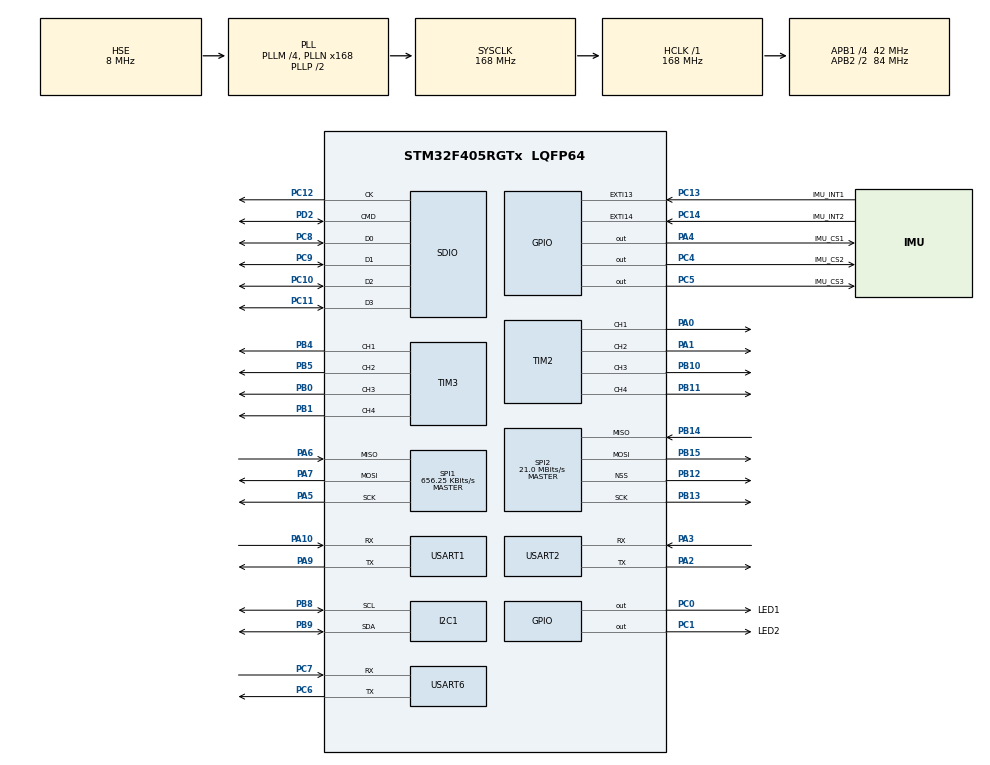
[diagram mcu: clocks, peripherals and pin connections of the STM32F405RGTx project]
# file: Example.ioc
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Mcu.Family=STM32F4
Mcu.Name=STM32F405RGTx
Mcu.Package=LQFP64
NVIC.PriorityGroup=NVIC_PRIORITYGROUP_4
PA0-WKUP.Signal=S_TIM2_CH1_ETR
PA1.Signal=S_TIM2_CH2
PA10.Mode=Asynchronous
PA10.Signal=USART1_RX
PA13.Mode=Serial_Wire
PA13.Signal=SYS_JTMS-SWDIO
PA14.Mode=Serial_Wire
PA14.Signal=SYS_JTCK-SWCLK
PA2.Mode=Asynchronous
PA2.Signal=USART2_TX
PA3.Mode=Asynchronous
PA3.Signal=USART2_RX
PA4.GPIO_Label=IMU_CS1
PA4.Signal=GPIO_Output
PA5.Mode=Full_Duplex_Master
PA5.Signal=SPI1_SCK
PA6.Mode=Full_Duplex_Master
PA6.Signal=SPI1_MISO
PA7.Mode=Full_Duplex_Master
PA7.Signal=SPI1_MOSI
PA9.Mode=Asynchronous
PA9.Signal=USART1_TX
PB0.Signal=S_TIM3_CH3
PB1.Signal=S_TIM3_CH4
PB10.Signal=S_TIM2_CH3
PB11.Signal=S_TIM2_CH4
PB12.Mode=NSS_Signal_Hard_Output
PB12.Signal=SPI2_NSS
PB13.Mode=Full_Duplex_Master
PB13.Signal=SPI2_SCK
PB14.Mode=Full_Duplex_Master
PB14.Signal=SPI2_MISO
PB15.Mode=Full_Duplex_Master
PB15.Signal=SPI2_MOSI
PB4.Signal=S_TIM3_CH1
PB5.Signal=S_TIM3_CH2
PB8.Mode=I2C
PB8.Signal=I2C1_SCL
PB9.Mode=I2C
PB9.Signal=I2C1_SDA
PC0.GPIO_Label=LED1
PC0.Signal=GPIO_Output
PC1.GPIO_Label=LED2
PC1.Signal=GPIO_Output
PC10.Mode=SD_4_bits_Wide_bus
PC10.Signal=SDIO_D2
PC11.Mode=SD_4_bits_Wide_bus
PC11.Signal=SDIO_D3
PC12.Mode=SD_4_bits_Wide_bus
PC12.Signal=SDIO_CK
PC13-ANTI_TAMP.GPIO_Label=IMU_INT1
PC13-ANTI_TAMP.Signal=GPXTI13
PC14-OSC32_IN.GPIO_Label=IMU_INT2
PC14-OSC32_IN.Signal=GPXTI14
PC4.GPIO_Label=IMU_CS2
PC4.Signal=GPIO_Output
PC5.GPIO_Label=IMU_CS3
PC5.Signal=GPIO_Output
PC6.Mode=Asynchronous
PC6.Signal=USART6_TX
PC7.Mode=Asynchronous
PC7.Signal=USART6_RX
PC8.Mode=SD_4_bits_Wide_bus
PC8.Signal=SDIO_D0
PC9.Mode=SD_4_bits_Wide_bus
PC9.Signal=SDIO_D1
PD2.Mode=SD_4_bits_Wide_bus
PD2.Signal=SDIO_CMD
PH0-OSC_IN.Mode=HSE-External-Oscillator
PH0-OSC_IN.Signal=RCC_OSC_IN
PH1-OSC_OUT.Mode=HSE-External-Oscillator
PH1-OSC_OUT.Signal=RCC_OSC_OUT
ProjectManager.HeapSize=0x200
ProjectManager.StackSize=0x400
ProjectManager.TargetToolchain=MDK-ARM V5
RCC.48MHZClocksFreq_Value=48000000
RCC.AHBFreq_Value=168000000
RCC.APB1CLKDivider=RCC_HCLK_DIV4
RCC.APB1Freq_Value=42000000
RCC.APB1TimFreq_Value=84000000
RCC.APB2CLKDivider=RCC_HCLK_DIV2
RCC.APB2Freq_Value=84000000
RCC.APB2TimFreq_Value=168000000
RCC.CortexFreq_Value=168000000
RCC.HCLKFreq_Value=168000000
RCC.HSE_VALUE=8000000
RCC.HSI_VALUE=16000000
RCC.LSE_VALUE=32768
RCC.PLLM=4
RCC.PLLN=168
RCC.PLLQ=7
RCC.PLLSourceVirtual=RCC_PLLSOURCE_HSE
RCC.SYSCLKFreq_VALUE=168000000
RCC.SYSCLKSource=RCC_SYSCLKSOURCE_PLLCLK
RCC.VCOOutputFreq_Value=336000000
SH.S_TIM2_CH1_ETR.0=TIM2_CH1,Output Compare1 CH1
SH.S_TIM2_CH2.0=TIM2_CH2,Output Compare2 CH2
SH.S_TIM2_CH3.0=TIM2_CH3,Output Compare3 CH3
SH.S_TIM2_CH4.0=TIM2_CH4,Output Compare4 CH4
SH.S_TIM3_CH1.0=TIM3_CH1,Output Compare1 CH1
SH.S_TIM3_CH2.0=TIM3_CH2,Output Compare2 CH2
SH.S_TIM3_CH3.0=TIM3_CH3,Output Compare3 CH3
SH.S_TIM3_CH4.0=TIM3_CH4,Output Compare4 CH4
SPI1.BaudRatePrescaler=SPI_BAUDRATEPRESCALER_128
SPI1.CalculateBaudRate=656.25 KBits/s
SPI1.Direction=SPI_DIRECTION_2LINES
SPI1.Mode=SPI_MODE_MASTER
SPI1.VirtualType=VM_MASTER
SPI2.CalculateBaudRate=21.0 MBits/s
SPI2.Direction=SPI_DIRECTION_2LINES
SPI2.Mode=SPI_MODE_MASTER
SPI2.VirtualNSS=VM_NSSHARD
SPI2.VirtualType=VM_MASTER
TIM2.Channel-Output\ Compare1\ CH1=TIM_CHANNEL_1
TIM2.Channel-Output\ Compare2\ CH2=TIM_CHANNEL_2
TIM2.Channel-Output\ Compare3\ CH3=TIM_CHANNEL_3
TIM2.Channel-Output\ Compare4\ CH4=TIM_CHANNEL_4
TIM3.Channel-Output\ Compare1\ CH1=TIM_CHANNEL_1
TIM3.Channel-Output\ Compare2\ CH2=TIM_CHANNEL_2
TIM3.Channel-Output\ Compare3\ CH3=TIM_CHANNEL_3
TIM3.Channel-Output\ Compare4\ CH4=TIM_CHANNEL_4
USART1.VirtualMode=VM_ASYNC
USART2.VirtualMode=VM_ASYNC
USART6.VirtualMode=VM_ASYNC
board=custom

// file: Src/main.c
/* USER CODE BEGIN Header */
/**
  ******************************************************************************
  * @file           : main.c
  * @brief          : Main program body
  ******************************************************************************
  ** This notice applies to any and all portions of this file
  * that are not between comment pairs USER CODE BEGIN and
  * USER CODE END. Other portions of this file, whether
  * inserted by the user or by software development tools
  * are owned by their respective copyright owners.
  *
  * COPYRIGHT(c) 2019 STMicroelectronics
  *
  * Redistribution and use in source and binary forms, with or without modification,
  * are permitted provided that the following conditions are met:
  *   1. Redistributions of source code must retain the above copyright notice,
  *      this list of conditions and the following disclaimer.
  *   2. Redistributions in binary form must reproduce the above copyright notice,
  *      this list of conditions and the following disclaimer in the documentation
  *      and/or other materials provided with the distribution.
  *   3. Neither the name of STMicroelectronics nor the names of its contributors
  *      may be used to endorse or promote products derived from this software
  *      without specific prior written permission.
  *
  * THIS SOFTWARE IS PROVIDED BY THE COPYRIGHT HOLDERS AND CONTRIBUTORS "AS IS"
  * AND ANY EXPRESS OR IMPLIED WARRANTIES, INCLUDING, BUT NOT LIMITED TO, THE
  * IMPLIED WARRANTIES OF MERCHANTABILITY AND FITNESS FOR A PARTICULAR PURPOSE ARE
  * DISCLAIMED. IN NO EVENT SHALL THE COPYRIGHT HOLDER OR CONTRIBUTORS BE LIABLE
  * FOR ANY DIRECT, INDIRECT, INCIDENTAL, SPECIAL, EXEMPLARY, OR CONSEQUENTIAL
  * DAMAGES (INCLUDING, BUT NOT LIMITED TO, PROCUREMENT OF SUBSTITUTE GOODS OR
  * SERVICES; LOSS OF USE, DATA, OR PROFITS; OR BUSINESS INTERRUPTION) HOWEVER
  * CAUSED AND ON ANY THEORY OF LIABILITY, WHETHER IN CONTRACT, STRICT LIABILITY,
  * OR TORT (INCLUDING NEGLIGENCE OR OTHERWISE) ARISING IN ANY WAY OUT OF THE USE
  * OF THIS SOFTWARE, EVEN IF ADVISED OF THE POSSIBILITY OF SUCH DAMAGE.
  *
  ******************************************************************************
  */
/* USER CODE END Header */

#include "main.h"

/* USER CODE BEGIN Includes */
#include "stdio.h"
/* USER CODE END Includes */

I2C_HandleTypeDef hi2c1;

SD_HandleTypeDef hsd;

SPI_HandleTypeDef hspi1;
SPI_HandleTypeDef hspi2;

TIM_HandleTypeDef htim2;
TIM_HandleTypeDef htim3;

UART_HandleTypeDef huart1;
UART_HandleTypeDef huart2;
UART_HandleTypeDef huart6;

/* USER CODE BEGIN PV */

//printf重定向
int fputc(int ch, FILE *f)
{
	HAL_UART_Transmit(&huart1, (uint8_t*) &ch,1, 10);
	return ch;
}
/* USER CODE END PV */

void SystemClock_Config(void);
static void MX_GPIO_Init(void);
static void MX_USART1_UART_Init(void);
static void MX_USART2_UART_Init(void);
static void MX_SPI1_Init(void);
static void MX_SDIO_SD_Init(void);
static void MX_USART6_UART_Init(void);
static void MX_SPI2_Init(void);
static void MX_I2C1_Init(void);
static void MX_TIM2_Init(void);
static void MX_TIM3_Init(void);

int main(void)
{

  /* MCU Configuration--------------------------------------------------------*/

  /* Reset of all peripherals, Initializes the Flash interface and the Systick. */
  HAL_Init();

  /* Configure the system clock */
  SystemClock_Config();

  /* Initialize all configured peripherals */
  MX_GPIO_Init();
  MX_USART1_UART_Init();
  MX_USART2_UART_Init();
  MX_SPI1_Init();
  MX_SDIO_SD_Init();
  MX_USART6_UART_Init();
  MX_SPI2_Init();
  MX_I2C1_Init();
  MX_TIM2_Init();
  MX_TIM3_Init();

  /* Infinite loop */
  /* USER CODE BEGIN WHILE */
  while (1)
  {
		printf("hello\n");
		HAL_Delay(500);
    /* USER CODE END WHILE */
  }
}

void SystemClock_Config(void)
{
  RCC_OscInitTypeDef RCC_OscInitStruct = {0};
  RCC_ClkInitTypeDef RCC_ClkInitStruct = {0};

  /**Configure the main internal regulator output voltage
  */
  __HAL_RCC_PWR_CLK_ENABLE();
  __HAL_PWR_VOLTAGESCALING_CONFIG(PWR_REGULATOR_VOLTAGE_SCALE1);
  /**Initializes the CPU, AHB and APB busses clocks
  */
  RCC_OscInitStruct.OscillatorType = RCC_OSCILLATORTYPE_HSE;
  RCC_OscInitStruct.HSEState = RCC_HSE_ON;
  RCC_OscInitStruct.PLL.PLLState = RCC_PLL_ON;
  RCC_OscInitStruct.PLL.PLLSource = RCC_PLLSOURCE_HSE;
  RCC_OscInitStruct.PLL.PLLM = 4;
  RCC_OscInitStruct.PLL.PLLN = 168;
  RCC_OscInitStruct.PLL.PLLP = RCC_PLLP_DIV2;
  RCC_OscInitStruct.PLL.PLLQ = 7;
  if (HAL_RCC_OscConfig(&RCC_OscInitStruct) != HAL_OK)
  {
    Error_Handler();
  }
  /**Initializes the CPU, AHB and APB busses clocks
  */
  RCC_ClkInitStruct.ClockType = RCC_CLOCKTYPE_HCLK|RCC_CLOCKTYPE_SYSCLK
                              |RCC_CLOCKTYPE_PCLK1|RCC_CLOCKTYPE_PCLK2;
  RCC_ClkInitStruct.SYSCLKSource = RCC_SYSCLKSOURCE_PLLCLK;
  RCC_ClkInitStruct.AHBCLKDivider = RCC_SYSCLK_DIV1;
  RCC_ClkInitStruct.APB1CLKDivider = RCC_HCLK_DIV4;
  RCC_ClkInitStruct.APB2CLKDivider = RCC_HCLK_DIV2;

  if (HAL_RCC_ClockConfig(&RCC_ClkInitStruct, FLASH_LATENCY_5) != HAL_OK)
  {
    Error_Handler();
  }
}

static void MX_I2C1_Init(void)
{

  hi2c1.Instance = I2C1;
  hi2c1.Init.ClockSpeed = 100000;
  hi2c1.Init.DutyCycle = I2C_DUTYCYCLE_2;
  hi2c1.Init.OwnAddress1 = 0;
  hi2c1.Init.AddressingMode = I2C_ADDRESSINGMODE_7BIT;
  hi2c1.Init.DualAddressMode = I2C_DUALADDRESS_DISABLE;
  hi2c1.Init.OwnAddress2 = 0;
  hi2c1.Init.GeneralCallMode = I2C_GENERALCALL_DISABLE;
  hi2c1.Init.NoStretchMode = I2C_NOSTRETCH_DISABLE;
  if (HAL_I2C_Init(&hi2c1) != HAL_OK)
  {
    Error_Handler();
  }

}

static void MX_SDIO_SD_Init(void)
{

  hsd.Instance = SDIO;
  hsd.Init.ClockEdge = SDIO_CLOCK_EDGE_RISING;
  hsd.Init.ClockBypass = SDIO_CLOCK_BYPASS_DISABLE;
  hsd.Init.ClockPowerSave = SDIO_CLOCK_POWER_SAVE_DISABLE;
  hsd.Init.BusWide = SDIO_BUS_WIDE_1B;
  hsd.Init.HardwareFlowControl = SDIO_HARDWARE_FLOW_CONTROL_DISABLE;
  hsd.Init.ClockDiv = 0;
  if (HAL_SD_Init(&hsd) != HAL_OK)
  {
    Error_Handler();
  }
  if (HAL_SD_ConfigWideBusOperation(&hsd, SDIO_BUS_WIDE_4B) != HAL_OK)
  {
    Error_Handler();
  }

}

static void MX_SPI1_Init(void)
{

  /* SPI1 parameter configuration*/
  hspi1.Instance = SPI1;
  hspi1.Init.Mode = SPI_MODE_MASTER;
  hspi1.Init.Direction = SPI_DIRECTION_2LINES;
  hspi1.Init.DataSize = SPI_DATASIZE_8BIT;
  hspi1.Init.CLKPolarity = SPI_POLARITY_LOW;
  hspi1.Init.CLKPhase = SPI_PHASE_1EDGE;
  hspi1.Init.NSS = SPI_NSS_SOFT;
  hspi1.Init.BaudRatePrescaler = SPI_BAUDRATEPRESCALER_2;
  hspi1.Init.FirstBit = SPI_FIRSTBIT_MSB;
  hspi1.Init.TIMode = SPI_TIMODE_DISABLE;
  hspi1.Init.CRCCalculation = SPI_CRCCALCULATION_DISABLE;
  hspi1.Init.CRCPolynomial = 10;
  if (HAL_SPI_Init(&hspi1) != HAL_OK)
  {
    Error_Handler();
  }

}

static void MX_SPI2_Init(void)
{

  /* SPI2 parameter configuration*/
  hspi2.Instance = SPI2;
  hspi2.Init.Mode = SPI_MODE_MASTER;
  hspi2.Init.Direction = SPI_DIRECTION_2LINES;
  hspi2.Init.DataSize = SPI_DATASIZE_8BIT;
  hspi2.Init.CLKPolarity = SPI_POLARITY_LOW;
  hspi2.Init.CLKPhase = SPI_PHASE_1EDGE;
  hspi2.Init.NSS = SPI_NSS_HARD_OUTPUT;
  hspi2.Init.BaudRatePrescaler = SPI_BAUDRATEPRESCALER_2;
  hspi2.Init.FirstBit = SPI_FIRSTBIT_MSB;
  hspi2.Init.TIMode = SPI_TIMODE_DISABLE;
  hspi2.Init.CRCCalculation = SPI_CRCCALCULATION_DISABLE;
  hspi2.Init.CRCPolynomial = 10;
  if (HAL_SPI_Init(&hspi2) != HAL_OK)
  {
    Error_Handler();
  }

}

static void MX_TIM2_Init(void)
{

  TIM_MasterConfigTypeDef sMasterConfig = {0};
  TIM_OC_InitTypeDef sConfigOC = {0};

  htim2.Instance = TIM2;
  htim2.Init.Prescaler = 0;
  htim2.Init.CounterMode = TIM_COUNTERMODE_UP;
  htim2.Init.Period = 0;
  htim2.Init.ClockDivision = TIM_CLOCKDIVISION_DIV1;
  if (HAL_TIM_OC_Init(&htim2) != HAL_OK)
  {
    Error_Handler();
  }
  sMasterConfig.MasterOutputTrigger = TIM_TRGO_RESET;
  sMasterConfig.MasterSlaveMode = TIM_MASTERSLAVEMODE_DISABLE;
  if (HAL_TIMEx_MasterConfigSynchronization(&htim2, &sMasterConfig) != HAL_OK)
  {
    Error_Handler();
  }
  sConfigOC.OCMode = TIM_OCMODE_TIMING;
  sConfigOC.Pulse = 0;
  sConfigOC.OCPolarity = TIM_OCPOLARITY_HIGH;
  sConfigOC.OCFastMode = TIM_OCFAST_DISABLE;
  if (HAL_TIM_OC_ConfigChannel(&htim2, &sConfigOC, TIM_CHANNEL_1) != HAL_OK)
  {
    Error_Handler();
  }
  if (HAL_TIM_OC_ConfigChannel(&htim2, &sConfigOC, TIM_CHANNEL_2) != HAL_OK)
  {
    Error_Handler();
  }
  if (HAL_TIM_OC_ConfigChannel(&htim2, &sConfigOC, TIM_CHANNEL_3) != HAL_OK)
  {
    Error_Handler();
  }
  if (HAL_TIM_OC_ConfigChannel(&htim2, &sConfigOC, TIM_CHANNEL_4) != HAL_OK)
  {
    Error_Handler();
  }
  HAL_TIM_MspPostInit(&htim2);

}

static void MX_TIM3_Init(void)
{

  TIM_MasterConfigTypeDef sMasterConfig = {0};
  TIM_OC_InitTypeDef sConfigOC = {0};

  htim3.Instance = TIM3;
  htim3.Init.Prescaler = 0;
  htim3.Init.CounterMode = TIM_COUNTERMODE_UP;
  htim3.Init.Period = 0;
  htim3.Init.ClockDivision = TIM_CLOCKDIVISION_DIV1;
  if (HAL_TIM_OC_Init(&htim3) != HAL_OK)
  {
    Error_Handler();
  }
  sMasterConfig.MasterOutputTrigger = TIM_TRGO_RESET;
  sMasterConfig.MasterSlaveMode = TIM_MASTERSLAVEMODE_DISABLE;
  if (HAL_TIMEx_MasterConfigSynchronization(&htim3, &sMasterConfig) != HAL_OK)
  {
    Error_Handler();
  }
  sConfigOC.OCMode = TIM_OCMODE_TIMING;
  sConfigOC.Pulse = 0;
  sConfigOC.OCPolarity = TIM_OCPOLARITY_HIGH;
  sConfigOC.OCFastMode = TIM_OCFAST_DISABLE;
  if (HAL_TIM_OC_ConfigChannel(&htim3, &sConfigOC, TIM_CHANNEL_1) != HAL_OK)
  {
    Error_Handler();
  }
  if (HAL_TIM_OC_ConfigChannel(&htim3, &sConfigOC, TIM_CHANNEL_2) != HAL_OK)
  {
    Error_Handler();
  }
  if (HAL_TIM_OC_ConfigChannel(&htim3, &sConfigOC, TIM_CHANNEL_3) != HAL_OK)
  {
    Error_Handler();
  }
  if (HAL_TIM_OC_ConfigChannel(&htim3, &sConfigOC, TIM_CHANNEL_4) != HAL_OK)
  {
    Error_Handler();
  }
  HAL_TIM_MspPostInit(&htim3);

}

static void MX_USART1_UART_Init(void)
{

  huart1.Instance = USART1;
  huart1.Init.BaudRate = 115200;
  huart1.Init.WordLength = UART_WORDLENGTH_8B;
  huart1.Init.StopBits = UART_STOPBITS_1;
  huart1.Init.Parity = UART_PARITY_NONE;
  huart1.Init.Mode = UART_MODE_TX_RX;
  huart1.Init.HwFlowCtl = UART_HWCONTROL_NONE;
  huart1.Init.OverSampling = UART_OVERSAMPLING_16;
  if (HAL_UART_Init(&huart1) != HAL_OK)
  {
    Error_Handler();
  }

}

static void MX_USART2_UART_Init(void)
{

  huart2.Instance = USART2;
  huart2.Init.BaudRate = 115200;
  huart2.Init.WordLength = UART_WORDLENGTH_8B;
  huart2.Init.StopBits = UART_STOPBITS_1;
  huart2.Init.Parity = UART_PARITY_NONE;
  huart2.Init.Mode = UART_MODE_TX_RX;
  huart2.Init.HwFlowCtl = UART_HWCONTROL_NONE;
  huart2.Init.OverSampling = UART_OVERSAMPLING_16;
  if (HAL_UART_Init(&huart2) != HAL_OK)
  {
    Error_Handler();
  }

}

static void MX_USART6_UART_Init(void)
{

  huart6.Instance = USART6;
  huart6.Init.BaudRate = 115200;
  huart6.Init.WordLength = UART_WORDLENGTH_8B;
  huart6.Init.StopBits = UART_STOPBITS_1;
  huart6.Init.Parity = UART_PARITY_NONE;
  huart6.Init.Mode = UART_MODE_TX_RX;
  huart6.Init.HwFlowCtl = UART_HWCONTROL_NONE;
  huart6.Init.OverSampling = UART_OVERSAMPLING_16;
  if (HAL_UART_Init(&huart6) != HAL_OK)
  {
    Error_Handler();
  }

}

static void MX_GPIO_Init(void)
{
  GPIO_InitTypeDef GPIO_InitStruct = {0};

  /* GPIO Ports Clock Enable */
  __HAL_RCC_GPIOC_CLK_ENABLE();
  __HAL_RCC_GPIOH_CLK_ENABLE();
  __HAL_RCC_GPIOA_CLK_ENABLE();
  __HAL_RCC_GPIOB_CLK_ENABLE();
  __HAL_RCC_GPIOD_CLK_ENABLE();

  /*Configure GPIO pin Output Level */
  HAL_GPIO_WritePin(GPIOC, LED1_Pin|LED2_Pin|IMU_CS2_Pin|IMU_CS3_Pin, GPIO_PIN_RESET);

  /*Configure GPIO pin Output Level */
  HAL_GPIO_WritePin(IMU_CS1_GPIO_Port, IMU_CS1_Pin, GPIO_PIN_RESET);

  /*Configure GPIO pins : IMU_INT1_Pin IMU_INT2_Pin */
  GPIO_InitStruct.Pin = IMU_INT1_Pin|IMU_INT2_Pin;
  GPIO_InitStruct.Mode = GPIO_MODE_IT_RISING;
  GPIO_InitStruct.Pull = GPIO_NOPULL;
  HAL_GPIO_Init(GPIOC, &GPIO_InitStruct);

  /*Configure GPIO pins : LED1_Pin LED2_Pin IMU_CS2_Pin IMU_CS3_Pin */
  GPIO_InitStruct.Pin = LED1_Pin|LED2_Pin|IMU_CS2_Pin|IMU_CS3_Pin;
  GPIO_InitStruct.Mode = GPIO_MODE_OUTPUT_PP;
  GPIO_InitStruct.Pull = GPIO_NOPULL;
  GPIO_InitStruct.Speed = GPIO_SPEED_FREQ_LOW;
  HAL_GPIO_Init(GPIOC, &GPIO_InitStruct);

  /*Configure GPIO pin : IMU_CS1_Pin */
  GPIO_InitStruct.Pin = IMU_CS1_Pin;
  GPIO_InitStruct.Mode = GPIO_MODE_OUTPUT_PP;
  GPIO_InitStruct.Pull = GPIO_NOPULL;
  GPIO_InitStruct.Speed = GPIO_SPEED_FREQ_LOW;
  HAL_GPIO_Init(IMU_CS1_GPIO_Port, &GPIO_InitStruct);

}

void Error_Handler(void)
{
}

/************************ (C) COPYRIGHT STMicroelectronics *****END OF FILE****/
